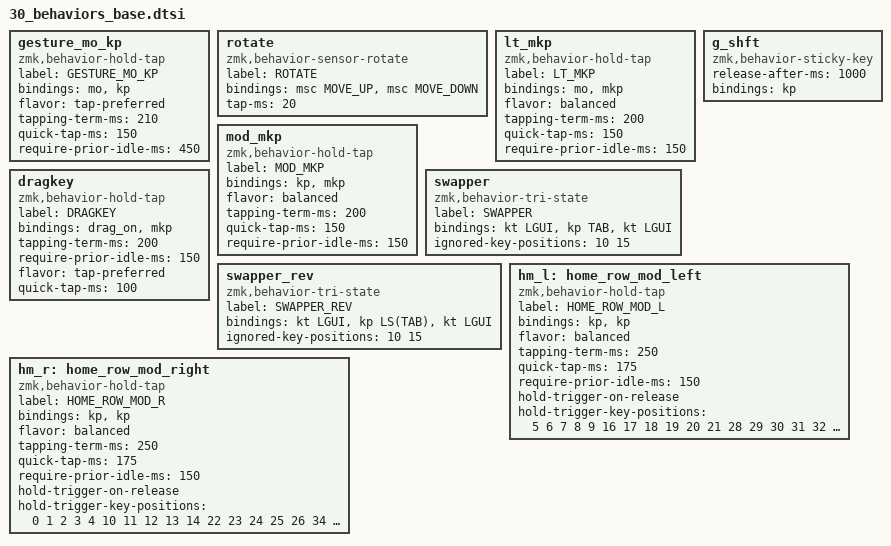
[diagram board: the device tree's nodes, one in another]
/* ============================================================
 * 30_behaviors_base.dtsi — 基礎 behavior 定義
 *
 * behaviors { } の内側でインクルードされる。
 * hold-tap / sensor-rotate / sticky-key / tri-state 系。
 * ============================================================ */

gesture_mo_kp: gesture_mo_kp {
    compatible = "zmk,behavior-hold-tap";
    label = "GESTURE_MO_KP";
    bindings = <&mo>, <&kp>;

    #binding-cells = <2>;
    flavor = "tap-preferred";
    tapping-term-ms = <210>;
    quick-tap-ms = <150>;
    require-prior-idle-ms = <450>;
};

rotate: rotate {
    compatible = "zmk,behavior-sensor-rotate";
    label = "ROTATE";
    #sensor-binding-cells = <0>;
    bindings = <&msc MOVE_UP>, <&msc MOVE_DOWN>;

    tap-ms = <20>;
};

lt_mkp: lt_mkp {
    compatible = "zmk,behavior-hold-tap";
    label = "LT_MKP";
    bindings = <&mo>, <&mkp>;

    #binding-cells = <2>;
    flavor = "balanced";
    tapping-term-ms = <200>;
    quick-tap-ms = <150>;
    require-prior-idle-ms = <150>;
};

mod_mkp: mod_mkp {
    compatible = "zmk,behavior-hold-tap";
    label = "MOD_MKP";
    bindings = <&kp>, <&mkp>;

    #binding-cells = <2>;
    flavor = "balanced";
    tapping-term-ms = <200>;
    quick-tap-ms = <150>;
    require-prior-idle-ms = <150>;
};

dragkey: dragkey {
    compatible = "zmk,behavior-hold-tap";
    label = "DRAGKEY";
    bindings = <&drag_on>, <&mkp>;

    #binding-cells = <2>;
    tapping-term-ms = <200>;
    require-prior-idle-ms = <150>;
    flavor = "tap-preferred";
    quick-tap-ms = <100>;
};

g_shft: g_shft {
    compatible = "zmk,behavior-sticky-key";
    #binding-cells = <1>;
    release-after-ms = <1000>;
    bindings = <&kp>;
};

swapper: swapper {
    compatible = "zmk,behavior-tri-state";
    label = "SWAPPER";
    #binding-cells = <0>;
    bindings = <&kt LGUI>, <&kp TAB>, <&kt LGUI>;

    ignored-key-positions = <10 15>;
};

swapper_rev: swapper_rev {
    compatible = "zmk,behavior-tri-state";
    label = "SWAPPER_REV";
    #binding-cells = <0>;
    bindings = <&kt LGUI>, <&kp LS(TAB)>, <&kt LGUI>;

    ignored-key-positions = <10 15>;
};

hm_l: home_row_mod_left {
    compatible = "zmk,behavior-hold-tap";
    label = "HOME_ROW_MOD_L";
    bindings = <&kp>, <&kp>;
    #binding-cells = <2>;
    flavor = "balanced";
    tapping-term-ms = <250>;
    quick-tap-ms = <175>;
    require-prior-idle-ms = <150>;
    hold-trigger-on-release;
    hold-trigger-key-positions = <5 6 7 8 9 16 17 18 19 20 21 28 29 30 31 32 33 45>;
};

hm_r: home_row_mod_right {
    compatible = "zmk,behavior-hold-tap";
    label = "HOME_ROW_MOD_R";
    bindings = <&kp>, <&kp>;
    #binding-cells = <2>;
    flavor = "balanced";
    tapping-term-ms = <250>;
    quick-tap-ms = <175>;
    require-prior-idle-ms = <150>;
    hold-trigger-on-release;
    hold-trigger-key-positions = <0 1 2 3 4 10 11 12 13 14 22 23 24 25 26 34 35 36 37 38>;
};
